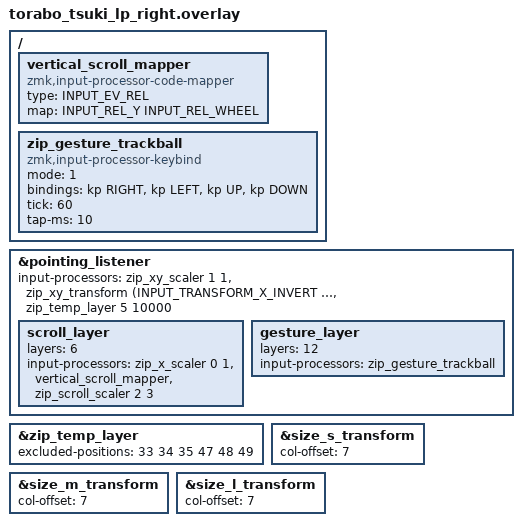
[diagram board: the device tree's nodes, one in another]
#include "torabo_tsuki_lp.dtsi"
#include <input/processors.dtsi>
#include <dt-bindings/zmk/input_transform.h>
#include <dt-bindings/input/input-event-codes.h>
#include <dt-bindings/zmk/keys.h>
#include <dt-bindings/zmk/modifiers.h>

/ {
    vertical_scroll_mapper: vertical_scroll_mapper {
        compatible = "zmk,input-processor-code-mapper";
        #input-processor-cells = <0>;
        type = <INPUT_EV_REL>;
        map = <INPUT_REL_Y INPUT_REL_WHEEL>;
    };
};

&pointing_listener {
    input-processors =
        <&zip_xy_scaler 1 1>, <&zip_xy_transform (INPUT_TRANSFORM_X_INVERT | INPUT_TRANSFORM_Y_INVERT)>,
        <&zip_temp_layer 5 10000>;

    scroll_layer {
        layers = <6>;
        input-processors =
            <&zip_x_scaler 0 1>,
            <&vertical_scroll_mapper>,
            <&zip_scroll_scaler 2 3>;
    };
};

&zip_temp_layer {
    excluded-positions = <33 34 35 47 48 49>;
};

&size_s_transform {
    col-offset = <7>;
};

&size_m_transform {
    col-offset = <7>;
};

&size_l_transform {
    col-offset = <7>;
};

/* === keymap-editor: gesture config (auto-generated, safe to regenerate) === */
/ {
    zip_gesture_trackball: zip_gesture_trackball {
        compatible = "zmk,input-processor-keybind";
        #input-processor-cells = <0>;
        mode = <1>;
        bindings = <&kp RIGHT>, <&kp LEFT>, <&kp UP>, <&kp DOWN>;
        tick = <60>;
        tap-ms = <10>;
    };
};

&pointing_listener {
    gesture_layer {
        layers = <12>;
        input-processors = <&zip_gesture_trackball>;
    };
};
/* === keymap-editor: end gesture config === */


